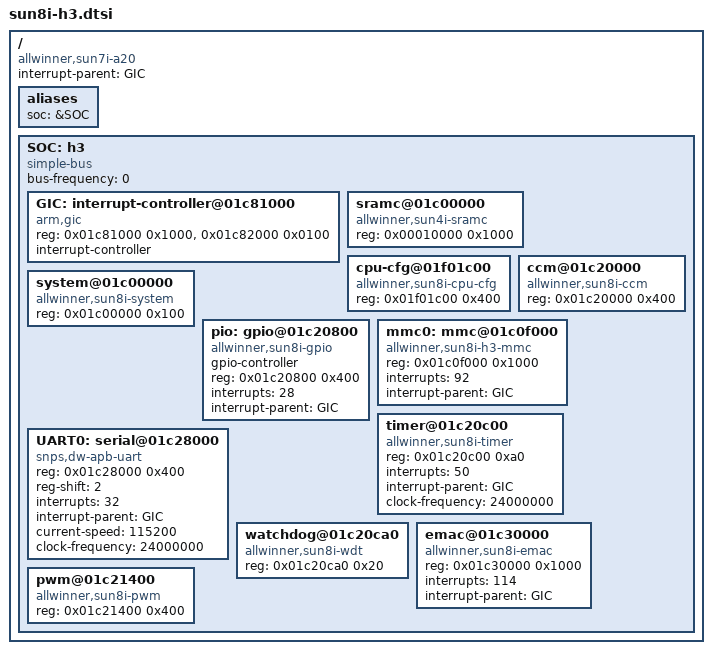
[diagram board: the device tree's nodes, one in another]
/*-
 * Copyright (c) 2014 Ganbold Tsagaankhuu <ganbold@freebsd.org>
 * All rights reserved.
 *
 * Redistribution and use in source and binary forms, with or without
 * modification, are permitted provided that the following conditions
 * are met:
 * 1. Redistributions of source code must retain the above copyright
 *    notice, this list of conditions and the following disclaimer.
 * 2. Redistributions in binary form must reproduce the above copyright
 *    notice, this list of conditions and the following disclaimer in the
 *    documentation and/or other materials provided with the distribution.
 *
 * THIS SOFTWARE IS PROVIDED BY THE AUTHOR AND CONTRIBUTORS ``AS IS'' AND
 * ANY EXPRESS OR IMPLIED WARRANTIES, INCLUDING, BUT NOT LIMITED TO, THE
 * IMPLIED WARRANTIES OF MERCHANTABILITY AND FITNESS FOR A PARTICULAR PURPOSE
 * ARE DISCLAIMED.  IN NO EVENT SHALL THE AUTHOR OR CONTRIBUTORS BE LIABLE
 * FOR ANY DIRECT, INDIRECT, INCIDENTAL, SPECIAL, EXEMPLARY, OR CONSEQUENTIAL
 * DAMAGES (INCLUDING, BUT NOT LIMITED TO, PROCUREMENT OF SUBSTITUTE GOODS
 * OR SERVICES; LOSS OF USE, DATA, OR PROFITS; OR BUSINESS INTERRUPTION)
 * HOWEVER CAUSED AND ON ANY THEORY OF LIABILITY, WHETHER IN CONTRACT, STRICT
 * LIABILITY, OR TORT (INCLUDING NEGLIGENCE OR OTHERWISE) ARISING IN ANY WAY
 * OUT OF THE USE OF THIS SOFTWARE, EVEN IF ADVISED OF THE POSSIBILITY OF
 * SUCH DAMAGE.
 *
 * $FreeBSD$
 */

/ {
	compatible = "allwinner,sun7i-a20";
	#address-cells = <1>;
	#size-cells = <1>;

	interrupt-parent = <&GIC>;

	aliases {
		soc = &SOC;
	};

	SOC: h3 {
		#address-cells = <1>;
		#size-cells = <1>;
		compatible = "simple-bus";
		ranges;
		bus-frequency = <0>;

		GIC: interrupt-controller@01c81000 {
			compatible = "arm,gic";
			reg = 	<0x01c81000 0x1000>,	/* Distributor Registers */
				<0x01c82000 0x0100>;	/* CPU Interface Registers */
			interrupt-controller;
			#interrupt-cells = <1>;
		};

		sramc@01c00000 {
			compatible = "allwinner,sun4i-sramc";
			#address-cells = <1>;
			#size-cells = <1>;
			reg = < 0x00010000 0x1000 >;
		};

		cpu-cfg@01f01c00 {
			compatible = "allwinner,sun8i-cpu-cfg";
			#address-cells = <1>;
			#size-cells = <1>;
			reg = < 0x01f01c00 0x400 >;
		};

		ccm@01c20000 {
			compatible = "allwinner,sun8i-ccm";
			#address-cells = <1>;
			#size-cells = <1>;
			reg = < 0x01c20000 0x400 >;
		};

		system@01c00000 {
			compatible = "allwinner,sun8i-system";
			#address-cells = <1>;
			#size-cells = <1>;
			reg = < 0x01c00000 0x100 >;
			status = "okay";
		};

		pio: gpio@01c20800 {
			#gpio-cells = <3>;
			compatible = "allwinner,sun8i-gpio";
			gpio-controller;
			reg =<  0x01c20800 0x400 >;
			interrupts = < 28 >;
			interrupt-parent = <&GIC>;
		};

		mmc0: mmc@01c0f000 {
			compatible = "allwinner,sun8i-h3-mmc";
			reg = <0x01c0f000 0x1000>;
			interrupts = <92>;
			interrupt-parent = <&GIC>;
			status = "okay";
		};

		timer@01c20c00 {
			compatible = "allwinner,sun8i-timer";
			reg = <0x01c20c00 0xa0>;
			interrupts = < 50 >;
			interrupt-parent = <&GIC>;
			clock-frequency = < 24000000 >;
		};

		UART0: serial@01c28000 {
			compatible = "snps,dw-apb-uart";
			reg = <0x01c28000 0x400>;
			reg-shift = <2>;
			interrupts = <32>;
			interrupt-parent = <&GIC>;
			current-speed = <115200>;
			clock-frequency = < 24000000 >;
		};
	
		watchdog@01c20ca0 {
			compatible = "allwinner,sun8i-wdt";
			status = "okay"; 
			reg = <0x01c20ca0 0x20>;
		};

		emac@01c30000 {
			compatible = "allwinner,sun8i-emac";
			reg = <0x01c30000 0x1000>;
			interrupts = <114>;
			interrupt-parent = <&GIC>;
			status = "okay";
		};

		pwm@01c21400 {
			compatible = "allwinner,sun8i-pwm";
			reg = <0x01c21400 0x400>;
			status = "okay";
		};
	};
};
